# bao1x register map
Vendor: baochip; File version: 1.0
Registers are 32-bit, read-write, reset 0x0 unless marked. A register's access mark holds for its fields unless they carry their own. Offsets are from the block's base; [hi:lo] are bit positions; {n}, {i} and the like mark numbered series.

## IRQARRAY10
Base 0xE0006000
0x00 EV_SOFT — Software interrupt trigger register. ) Bits set to `1` will trigger an interrupt. Interrupts trigger on write, but the value will persist in the register, allowing software to determine if a software interrupt was triggered by reading back the register. Software is responsible for clearing the register to 0. Repeated `1` writes without clearing will still trigger an interrupt.
  [15:0] trigger
0x04 EV_EDGE_TRIGGERED — If a bit is set to 1, then the hardware trigger is edge-triggered
  [15:0] use_edge
0x08 EV_POLARITY — If a bit is set to 1, then the polarity is rising edge triggered; 0 is falling edge triggered. Bit is ignored if `edge_triggered` is 0.
  [15:0] rising
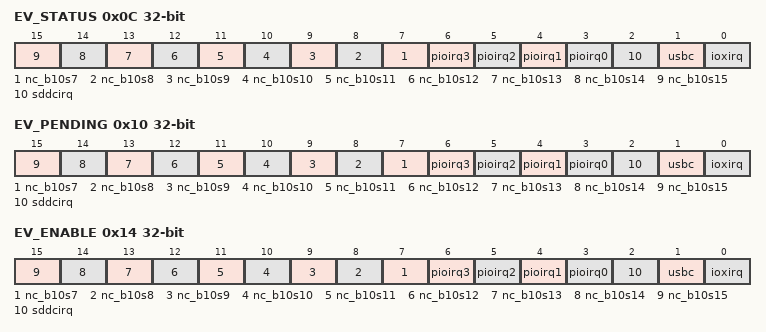
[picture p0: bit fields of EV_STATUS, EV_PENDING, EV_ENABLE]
0x0C EV_STATUS — `1` when a "nc_b10s15" event occurs. This event uses an `EventSourceFlex` form of triggering
  [n] nc_b10s{n} (n=7..15) — Level of the ``nc_b10s{n}`` event
  [n+3] pioirq{n} (n=0..3) — Level of the ``pioirq{n}`` event
  [2] sddcirq — Level of the ``sddcirq`` event
  [1] usbc — Level of the ``usbc`` event
  [0] ioxirq — Level of the ``ioxirq`` event
0x10 EV_PENDING — `1` when a "nc_b10s15" event occurs. This event uses an `EventSourceFlex` form of triggering
  [n] nc_b10s{n} (n=7..15) — `1` when a "nc_b10s{n}" event occurs. This event uses an `EventSourceFlex` form of triggering
  [n+3] pioirq{n} (n=0..3) — `1` when a "pioirq{n}" event occurs. This event uses an `EventSourceFlex` form of triggering
  [2] sddcirq — `1` when a "sddcirq" event occurs. This event uses an `EventSourceFlex` form of triggering
  [1] usbc — `1` when a "usbc" event occurs. This event uses an `EventSourceFlex` form of triggering
  [0] ioxirq — `1` when a "ioxirq" event occurs. This event uses an `EventSourceFlex` form of triggering
0x14 EV_ENABLE — `1` when a "nc_b10s15" event occurs. This event uses an `EventSourceFlex` form of triggering
  [n] nc_b10s{n} (n=7..15) — Write a ``1`` to enable the ``nc_b10s{n}`` Event
  [n+3] pioirq{n} (n=0..3) — Write a ``1`` to enable the ``pioirq{n}`` Event
  [2] sddcirq — Write a ``1`` to enable the ``sddcirq`` Event
  [1] usbc — Write a ``1`` to enable the ``usbc`` Event
  [0] ioxirq — Write a ``1`` to enable the ``ioxirq`` Event

## IRQARRAY11
Base 0xE0007000
0x00 EV_SOFT — Software interrupt trigger register. ) Bits set to `1` will trigger an interrupt. Interrupts trigger on write, but the value will persist in the register, allowing software to determine if a software interrupt was triggered by reading back the register. Software is responsible for clearing the register to 0. Repeated `1` writes without clearing will still trigger an interrupt.
  [15:0] trigger
0x04 EV_EDGE_TRIGGERED — If a bit is set to 1, then the hardware trigger is edge-triggered
  [15:0] use_edge
0x08 EV_POLARITY — If a bit is set to 1, then the polarity is rising edge triggered; 0 is falling edge triggered. Bit is ignored if `edge_triggered` is 0.
  [15:0] rising
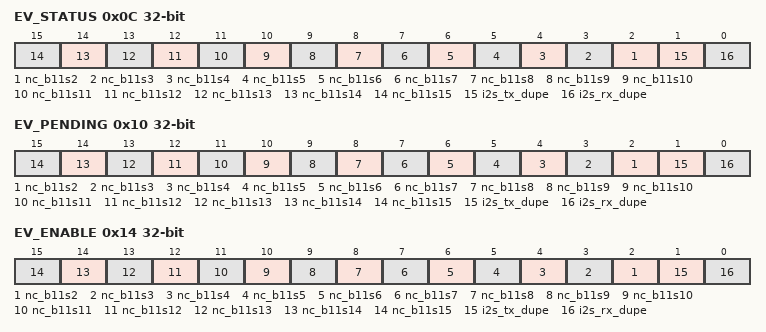
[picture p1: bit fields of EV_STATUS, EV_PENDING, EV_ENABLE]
0x0C EV_STATUS — `1` when a "nc_b11s15" event occurs. This event uses an `EventSourceFlex` form of triggering
  [n] nc_b11s{n} (n=2..15) — Level of the ``nc_b11s{n}`` event
  [1] i2s_tx_dupe — Level of the ``i2s_tx_dupe`` event
  [0] i2s_rx_dupe — Level of the ``i2s_rx_dupe`` event
0x10 EV_PENDING — `1` when a "nc_b11s15" event occurs. This event uses an `EventSourceFlex` form of triggering
  [n] nc_b11s{n} (n=2..15) — `1` when a "nc_b11s{n}" event occurs. This event uses an `EventSourceFlex` form of triggering
  [1] i2s_tx_dupe — `1` when a "i2s_tx_dupe" event occurs. This event uses an `EventSourceFlex` form of triggering
  [0] i2s_rx_dupe — `1` when a "i2s_rx_dupe" event occurs. This event uses an `EventSourceFlex` form of triggering
0x14 EV_ENABLE — `1` when a "nc_b11s15" event occurs. This event uses an `EventSourceFlex` form of triggering
  [n] nc_b11s{n} (n=2..15) — Write a ``1`` to enable the ``nc_b11s{n}`` Event
  [1] i2s_tx_dupe — Write a ``1`` to enable the ``i2s_tx_dupe`` Event
  [0] i2s_rx_dupe — Write a ``1`` to enable the ``i2s_rx_dupe`` Event
